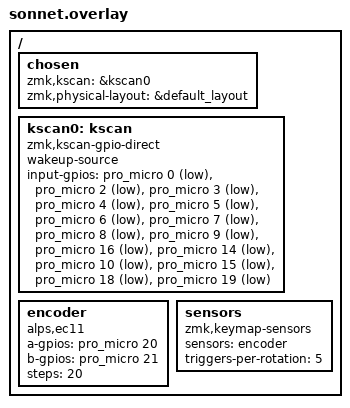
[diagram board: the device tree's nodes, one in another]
// Sonnet 键盘 - 14键 + EC11编码器 + 蓝牙
// 使用 direct GPIO 接线（非正交矩阵）
// 主控: nice!nano (nRF52840)
//
// 实际物理布局:
//         ┌────┬────┬────┬────┬────┐
// 第1行:  │ S1 │ S2 │ S3 │ S4 │ S5 │  5键 (D0, D2, D3, D4, D5)
//         ├────┼────┼────┼────┼────┼────┐
// 第2行:  │ S6 │ S7 │ S8 │ S9 │S11 │S12 │  6键 (D6, D7, D8, D9, D16, D14)
//         ├────┼────┼────┤         │
// 第3行:  │S10 │S13 │S14 │  编码器  │  3键 + 编码器 (D10, D15, D18)
//         └────┴────┴────┴──────────┘
// 编码器: 按键S15=D19, A相S16=D20, B相S17=D21

#include <dt-bindings/zmk/matrix_transform.h>

#include "sonnet-layouts.dtsi"

/ {
    chosen {
        zmk,kscan = &kscan0;
        zmk,physical-layout = &default_layout;
    };

    // Direct GPIO 按键扫描 - 每个按键独立占用一个 GPIO
    // 14个按键 + 1个编码器按键 = 15个输入
    kscan0: kscan {
        compatible = "zmk,kscan-gpio-direct";
        wakeup-source;

        input-gpios
            // 第1行 (5键): S1~S5
            = <&pro_micro  0 (GPIO_ACTIVE_LOW | GPIO_PULL_UP)>  // S1  D0  pos0
            , <&pro_micro  2 (GPIO_ACTIVE_LOW | GPIO_PULL_UP)>  // S2  D2  pos1
            , <&pro_micro  3 (GPIO_ACTIVE_LOW | GPIO_PULL_UP)>  // S3  D3  pos2
            , <&pro_micro  4 (GPIO_ACTIVE_LOW | GPIO_PULL_UP)>  // S4  D4  pos3
            , <&pro_micro  5 (GPIO_ACTIVE_LOW | GPIO_PULL_UP)>  // S5  D5  pos4
            // 第2行 (6键): S6, S7, S8, S9, S11, S12
            , <&pro_micro  6 (GPIO_ACTIVE_LOW | GPIO_PULL_UP)>  // S6  D6  pos5
            , <&pro_micro  7 (GPIO_ACTIVE_LOW | GPIO_PULL_UP)>  // S7  D7  pos6
            , <&pro_micro  8 (GPIO_ACTIVE_LOW | GPIO_PULL_UP)>  // S8  D8  pos7
            , <&pro_micro  9 (GPIO_ACTIVE_LOW | GPIO_PULL_UP)>  // S9  D9  pos8
            , <&pro_micro 16 (GPIO_ACTIVE_LOW | GPIO_PULL_UP)>  // S11 D16 pos9
            , <&pro_micro 14 (GPIO_ACTIVE_LOW | GPIO_PULL_UP)>  // S12 D14 pos10
            // 第3行 (3键 + 编码器按键): S10, S13, S14, S15(编码器按键)
            , <&pro_micro 10 (GPIO_ACTIVE_LOW | GPIO_PULL_UP)>  // S10 D10 pos11
            , <&pro_micro 15 (GPIO_ACTIVE_LOW | GPIO_PULL_UP)>  // S13 D15 pos12
            , <&pro_micro 18 (GPIO_ACTIVE_LOW | GPIO_PULL_UP)>  // S14 D18 pos13
            // 编码器按下开关
            , <&pro_micro 19 (GPIO_ACTIVE_LOW | GPIO_PULL_UP)>  // S15 D19 pos14 编码器按键
            ;
    };

    // 注意：使用 zmk,kscan-gpio-direct 时，position = input-gpios 列表中的索引
    // 不需要 matrix-transform，keymap 的 bindings 直接按 position 顺序排列

    // EC11 编码器
    encoder: encoder {
        compatible = "alps,ec11";
        a-gpios = <&pro_micro 20 (GPIO_ACTIVE_HIGH | GPIO_PULL_UP)>;  // S16 D20 编码器A相
        b-gpios = <&pro_micro 21 (GPIO_ACTIVE_HIGH | GPIO_PULL_UP)>;  // S17 D21 编码器B相
        steps = <20>;
        status = "okay";
    };

    sensors: sensors {
        compatible = "zmk,keymap-sensors";
        sensors = <&encoder>;
        triggers-per-rotation = <5>;
    };
};
